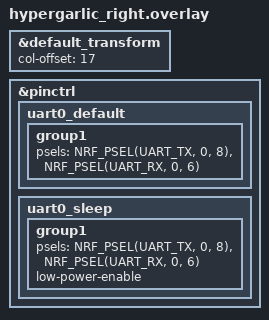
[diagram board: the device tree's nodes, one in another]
/*
 * Copyright (c) 2020 Pete Johanson
 *
 * SPDX-License-Identifier: MIT
 */
#include "hypergarlic.dtsi"

&default_transform {
	col-offset = <17>;
};



&pinctrl {
	uart0_default: uart0_default {
		group1 {
			psels = <NRF_PSEL(UART_TX, 0, 8)>,
				<NRF_PSEL(UART_RX, 0, 6)>;
		};
	};

	uart0_sleep: uart0_sleep {
		group1 {
			psels = <NRF_PSEL(UART_TX, 0, 8)>,
				<NRF_PSEL(UART_RX, 0, 6)>;
			low-power-enable;
		};
	};
};
